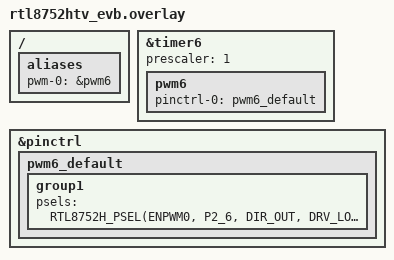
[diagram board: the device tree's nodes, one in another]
/*
 * Copyright(c) 2020, Realtek Semiconductor Corporation.
 *
 * SPDX-License-Identifier: Apache-2.0
 */

#include <zephyr/dt-bindings/pwm/pwm.h>
#include <dt-bindings/pinctrl/rtl8752h-pinctrl.h>

/ {
	aliases {
		pwm-0 = &pwm6;
	};
};

&timer6 {
	status = "okay";
	prescaler = <1>;
	pwm6: pwm6 {
		status = "okay";
		pinctrl-0 = <&pwm6_default>;
		pinctrl-names = "default";
	};
};

&pinctrl {
	pwm6_default: pwm6_default {
		group1 {
			psels = <RTL8752H_PSEL(ENPWM0, P2_6, DIR_OUT, DRV_LOW, PULL_DOWN)>;
		};
	};
};
